# R7FA6T2BD register map
Vendor: Renesas Electronics Corporation; Series: RA6; File version: 1.40.00
CPU: CM33 r0p4, little endian, MPU, FPU, VTOR, 4 interrupt priority bits, 96 interrupts
Registers are 32-bit, read-write, reset 0x0 unless marked. A register's access mark holds for its fields unless they carry their own. Offsets are from the block's base; [hi:lo] are bit positions; {n}, {i} and the like mark numbered series.

## SYSC — System Control
Base 0x4001E000
0x0C SBYCR 16-bit reset 0x4000 — Standby Control Register
  [15] SSBY — Software Standby Mode Select
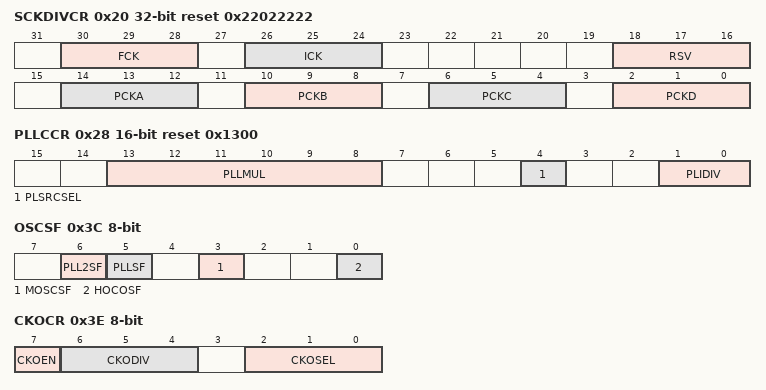
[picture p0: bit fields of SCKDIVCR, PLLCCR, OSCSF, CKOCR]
0x20 SCKDIVCR reset 0x22022222 — System Clock Division Control Register
  [30:28] FCK — FlashIF Clock (FCLK) Select
  [26:24] ICK — System Clock (ICLK) Select
  [18:16] RSV — Reserved. Set these bits to the same value as PCKB[2:0].
  [14:12] PCKA — Peripheral Module Clock A (PCLKA) Select
  [10:8] PCKB — Peripheral Module Clock B (PCLKB) Select
  [6:4] PCKC — Peripheral Module Clock C (PCLKC) Select
  [2:0] PCKD — Peripheral Module Clock D (PCLKD) Select
0x26 SCKSCR 8-bit reset 0x1 — System Clock Source Control Register
  [2:0] CKSEL — Clock Source Select
0x28 PLLCCR 16-bit reset 0x1300 — PLL Clock Control Register
  [13:8] PLLMUL range 0x13..0x3B — PLL Frequency Multiplication Factor Select
  [4] PLSRCSEL — PLL Clock Source Select
  [1:0] PLIDIV — PLL Input Frequency Division Ratio Select
0x2A PLLCR 8-bit reset 0x1 — PLL Control Register
  [0] PLLSTP — PLL Stop Control
0x32 MOSCCR 8-bit reset 0x1 — Main Clock Oscillator Control Register
  [0] MOSTP — Main Clock Oscillator Stop
0x36 HOCOCR 8-bit (reset mask 0xFE) — High,Speed On,Chip Oscillator Control Register
  [0] HCSTP — HOCO Stop
0x37 HOCOCR2 8-bit (reset mask 0xFC) — High,Speed On,Chip Oscillator Control Register 2
  [1:0] HCFRQ0 — HOCO Frequency Setting 0
0x38 MOCOCR 8-bit — Middle,Speed On,Chip Oscillator Control Register
  [0] MCSTP — MOCO Stop
0x3C OSCSF 8-bit ro (reset mask 0xFE) — Oscillation Stabilization Flag Register
  [6] PLL2SF — PLL2 Clock Oscillation Stabilization Flag
  [5] PLLSF — PLL Clock Oscillation Stabilization Flag
  [3] MOSCSF — Main Clock Oscillation Stabilization Flag
  [0] HOCOSF — HOCO Clock Oscillation Stabilization Flag
0x3E CKOCR 8-bit — Clock Out Control Register
  [7] CKOEN — Clock Out Enable
  [6:4] CKODIV — Clock Output Frequency Division Ratio
  [2:0] CKOSEL — Clock Out Source Select
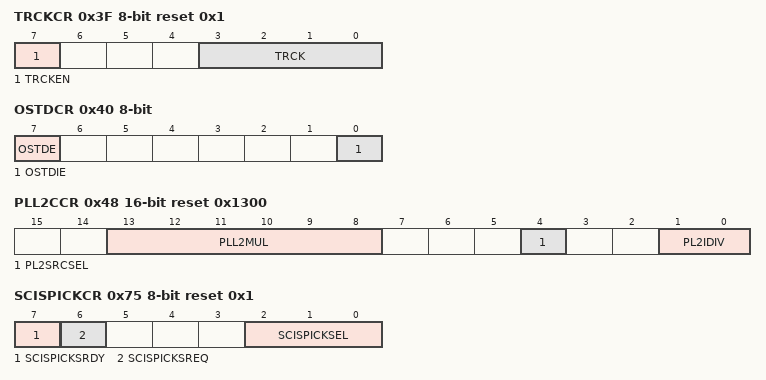
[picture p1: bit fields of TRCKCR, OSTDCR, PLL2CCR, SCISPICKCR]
0x3F TRCKCR 8-bit reset 0x1 — Trace Clock Control Register
  [7] TRCKEN — Trace Clock operating Enable
  [3:0] TRCK — Trace Clock operating frequency select
0x40 OSTDCR 8-bit — Oscillation Stop Detection Control Register
  [7] OSTDE — Oscillation Stop Detection Function Enable
  [0] OSTDIE — Oscillation Stop Detection Interrupt Enable
0x41 OSTDSR 8-bit — Oscillation Stop Detection Status Register
  [0] OSTDF — Oscillation Stop Detection Flag
0x48 PLL2CCR 16-bit reset 0x1300 — PLL2 Clock Control Register
  [13:8] PLL2MUL — PLL2 Frequency Multiplication Factor Select
  [4] PL2SRCSEL — PLL2 Clock Source Select
  [1:0] PL2IDIV — PLL2 Input Frequency Division Ratio Select
0x4A PLL2CR 8-bit reset 0x1 — PLL2 Control Register
  [0] PLL2STP — PLL2 Stop Control
0x61 MOCOUTCR 8-bit — MOCO User Trimming Control Register
  [7:0] MOCOUTRM — MOCO User Trimming
0x62 HOCOUTCR 8-bit — HOCO User Trimming Control Register
  [7:0] HOCOUTRM — HOCO User Trimming
0x6D SCISPICKDIVCR 8-bit — SCI SPI Clock Division Control Register
  [2:0] SCISPICKDIV — SCI SPI Clock (SCISPICLK) Division Select
0x6E CANFDCKDIVCR 8-bit — CANFD Clock Division Control Register
  [2:0] CANFDCKDIV — CANFD clock (CANFDCLK) Division Select
0x6F GPTCKDIVCR 8-bit — GPT Clock Division Control Register
  [2:0] GPTCKDIV — GPT clock (GPTCLK) Division Select
0x70 IICCKDIVCR 8-bit reset 0x1 — IIC Clock Division Control Register
  [2:0] IICCKDIV — IIC clock (IICCLK) Division Select
0x75 SCISPICKCR 8-bit reset 0x1 — SCI SPI Clock Control Register
  [7] SCISPICKSRDY ro — SCI SPI Clock (SCISPICLK) Switching Ready state flag
  [6] SCISPICKSREQ — SCI SPI Clock (SCISPICLK) Switching Request
  [2:0] SCISPICKSEL — SCI SPI Clock (SCISPICLK) Source Select
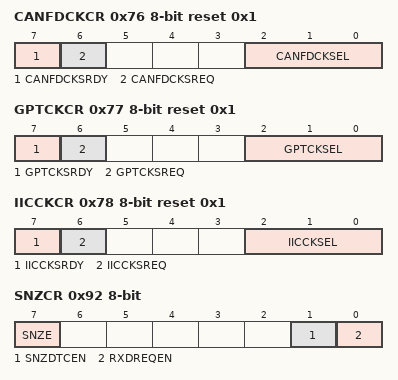
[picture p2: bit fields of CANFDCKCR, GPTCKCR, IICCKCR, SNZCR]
0x76 CANFDCKCR 8-bit reset 0x1 — CANFD Clock Control Register
  [7] CANFDCKSRDY ro — CANFD clock (CANFDCLK) Switching Ready state flag
  [6] CANFDCKSREQ — CANFD clock (CANFDCLK) Switching Request
  [2:0] CANFDCKSEL — CANFD clock (CANFDCLK) Source Select
0x77 GPTCKCR 8-bit reset 0x1 — GPT Clock Control Register
  [7] GPTCKSRDY ro — GPT clock (GPTCLK) Switching Ready state flag
  [6] GPTCKSREQ — GPT clock (GPTCLK) Switching Request
  [2:0] GPTCKSEL — GPT clock (GPTCLK) Source Select
0x78 IICCKCR 8-bit reset 0x1 — IIC Clock Control Register
  [7] IICCKSRDY ro — IIC clock (IICCLK) Switching Ready state flag
  [6] IICCKSREQ — IIC clock (IICCLK) Switching Request
  [2:0] IICCKSEL — IIC clock (IICCLK) Source Select
0x92 SNZCR 8-bit — Snooze Control Register
  [7] SNZE — Snooze mode Enable
  [1] SNZDTCEN — DTC Enable in Snooze mode
  [0] RXDREQEN — RXD0 Snooze Request Enable
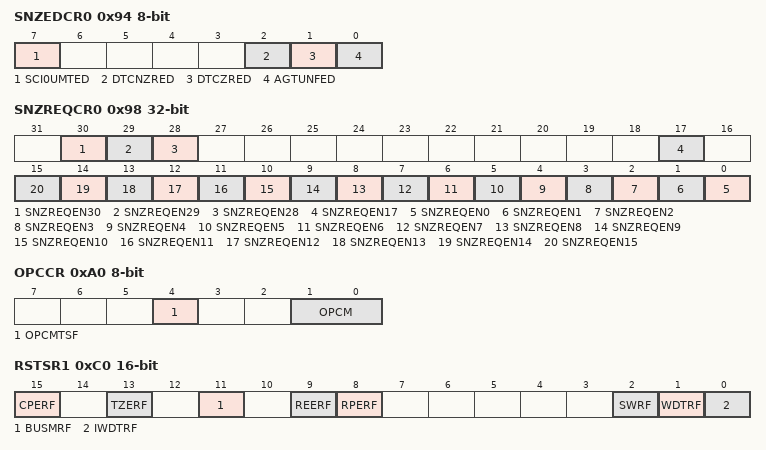
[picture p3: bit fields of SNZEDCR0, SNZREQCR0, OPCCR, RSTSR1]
0x94 SNZEDCR0 8-bit — Snooze End Control Register 0
  [7] SCI0UMTED — SCI0 Address Mismatch Snooze End Enable
  [2] DTCNZRED — Not Last DTC Transmission Completion Snooze End Enable
  [1] DTCZRED — Last DTC Transmission Completion Snooze End Enable
  [0] AGTUNFED — AGT1 Underflow Snooze End Enable
0x98 SNZREQCR0 — Snooze Request Control Register 0
  [30] SNZREQEN30 — Enable AGT1 compare match B snooze request
  [29] SNZREQEN29 — Enable AGT1 compare match A snooze request
  [28] SNZREQEN28 — Enable AGT1 underflow snooze request
  [17] SNZREQEN17 — Enable Key Interrupt snooze request
  [n] SNZREQEN{n} (n=0..15) — Enable IRQ{n} pin snooze request
0xA0 OPCCR 8-bit — Operating Power Control Register
  [4] OPCMTSF ro — Operating Power Control Mode Transition Status Flag
  [1:0] OPCM — Operating Power Control Mode Select
0xA2 MOSCWTCR 8-bit reset 0x5 — Main Clock Oscillator Wait Control Register
  [3:0] MSTS — Main Clock Oscillator Wait Time Setting
0xC0 RSTSR1 16-bit (reset mask 0x54F8) — Reset Status Register 1
  [15] CPERF — Cache Parity Error Reset Detect Flag
  [13] TZERF — TrustZone Error Reset Detect Flag
  [11] BUSMRF — Bus Master MPU Error Reset Detect Flag
  [9] REERF — SRAM ECC Error Reset Detect Flag
  [8] RPERF — SRAM Parity Error Reset Detect Flag
  [2] SWRF — Software Reset Detect Flag
  [1] WDTRF — Watchdog Timer Reset Detect Flag
  [0] IWDTRF — Independent Watchdog Timer Reset Detect Flag
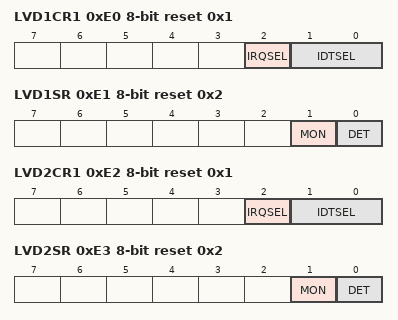
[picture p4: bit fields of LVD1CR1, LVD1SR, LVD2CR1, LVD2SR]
0xE0 LVD1CR1 8-bit reset 0x1 — Voltage Monitor 1 Circuit Control Register
  [2] IRQSEL — Voltage Monitor 1 Interrupt Type Select
  [1:0] IDTSEL — Voltage Monitor 1 Interrupt Generation Condition Select
0xE1 LVD1SR 8-bit reset 0x2 — Voltage Monitor 1 Circuit Status Register
  [1] MON ro — Voltage Monitor 1 Signal Monitor Flag
  [0] DET — Voltage Monitor 1 Voltage Variation Detection Flag
0xE2 LVD2CR1 8-bit reset 0x1 — Voltage Monitor 2 Circuit Control Register 1
  [2] IRQSEL — Voltage Monitor 2 Interrupt Type Select
  [1:0] IDTSEL — Voltage Monitor 2 Interrupt Generation Condition Select
0xE3 LVD2SR 8-bit reset 0x2 — Voltage Monitor 2 Circuit Status Register
  [1] MON ro — Voltage Monitor 2 Signal Monitor Flag
  [0] DET — Voltage Monitor 2 Voltage Variation Detection Flag
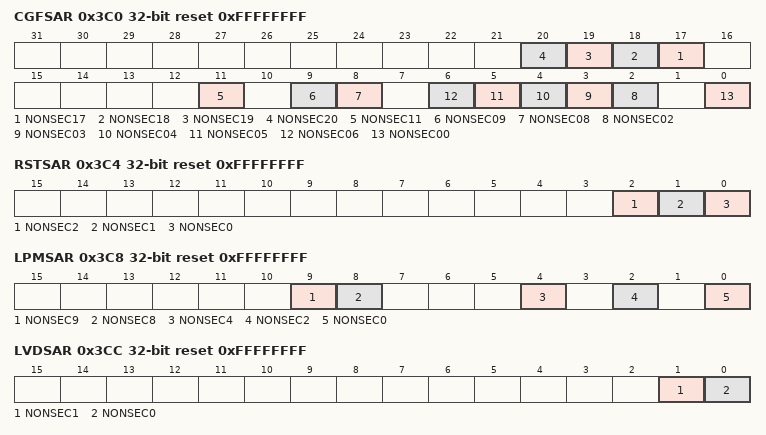
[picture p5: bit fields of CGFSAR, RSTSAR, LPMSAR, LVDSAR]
0x3C0 CGFSAR reset 0xFFFFFFFF — Clock Generation Function Security Attribute Register
  [n] NONSEC{n} (n=17..20) — Non Secure Attribute bit {n}
  [11] NONSEC11 — Non Secure Attribute bit 11
  [9] NONSEC09 — Non Secure Attribute bit 09
  [8] NONSEC08 — Non Secure Attribute bit 08
  [n] NONSEC{n:02} (n=2..6) — Non Secure Attribute bit {n:02}
  [0] NONSEC00 — Non Secure Attribute bit 00
0x3C4 RSTSAR reset 0xFFFFFFFF — Reset Security Attribution Register
  [2] NONSEC2 — Non Secure Attribute bit 2
  [1] NONSEC1 — Non Secure Attribute bit 1
  [0] NONSEC0 — Non Secure Attribute bit 0
0x3C8 LPMSAR reset 0xFFFFFFFF — Low Power Mode Security Attribution Register
  [9] NONSEC9 — Non Secure Attribute bit 9
  [8] NONSEC8 — Non Secure Attribute bit 8
  [4] NONSEC4 — Non Secure Attribute bit 4
  [2] NONSEC2 — Non Secure Attribute bit 2
  [0] NONSEC0 — Non Secure Attribute bit 0
0x3CC LVDSAR reset 0xFFFFFFFF — Low Voltage Detection Security Attribution Register
  [1] NONSEC1 — Non Secure Attribute bit 1
  [0] NONSEC0 — Non Secure Attribute bit 0
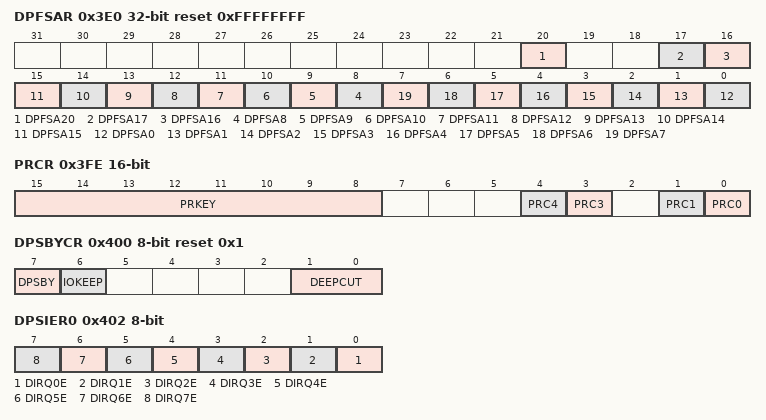
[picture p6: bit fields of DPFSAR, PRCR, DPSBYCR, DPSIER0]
0x3E0 DPFSAR reset 0xFFFFFFFF — Deep Software Standby Interrupt Factor Security Attribution Register
  [20] DPFSA20 — Deep Software Standby Interrupt Factor Security Attribute bit 20
  [17] DPFSA17 — Deep Software Standby Interrupt Factor Security Attribute bit 17
  [16] DPFSA16 — Deep Software Standby Interrupt Factor Security Attribute bit 16
  [n] DPFSA{n} (n=8..15) — Deep Software Standby Interrupt Factor Security Attribute bit n (n = 8 to 15)
  [n] DPFSA{n} (n=0..7) — Deep Software Standby Interrupt Factor Security Attribute bit n (n = 0 to 7)
0x3FE PRCR 16-bit — Protect Register
  [15:8] PRKEY wo — PRC Key Code
  [4] PRC4
  [3] PRC3 — Enable writing to the registers related to the LVD
  [1] PRC1 — Enable writing to the registers related to the low power modes
  [0] PRC0 — Enable writing to the registers related to the clock generation circuit
0x400 DPSBYCR 8-bit reset 0x1 — Deep Software Standby Control Register
  [7] DPSBY — Deep Software Standby
  [6] IOKEEP — I/O Port Rentention
  [1:0] DEEPCUT — Power,Supply Control
0x401 DPSWCR 8-bit reset 0x19 — Deep Software Standby Wait Control Register
  [5:0] WTSTS — Deep Software Wait Standby Time Setting Bit
0x402 DPSIER0 8-bit — Deep Software Standby Interrupt Enable Register 0
  [n] DIRQ{n}E (n=0..7) — IRQ{n}-DS Pin Enable
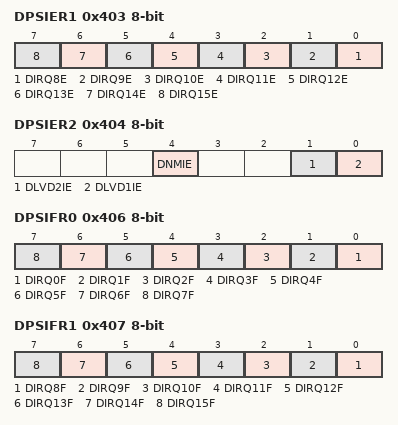
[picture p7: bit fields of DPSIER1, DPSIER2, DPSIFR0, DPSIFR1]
0x403 DPSIER1 8-bit — Deep Software Standby Interrupt Enable Register 1
  [n-8] DIRQ{n}E (n=8..15) — IRQ{n}-DS Pin Enable
0x404 DPSIER2 8-bit — Deep Software Standby Interrupt Enable Register 2
  [4] DNMIE — NMI Pin Enable
  [1] DLVD2IE — LVD2 Deep Software Standby Cancel Signal Enable
  [0] DLVD1IE — LVD1 Deep Software Standby Cancel Signal Enable
0x406 DPSIFR0 8-bit — Deep Software Standby Interrupt Flag Register 0
  [n] DIRQ{n}F (n=0..7) — IRQ{n}-DS Pin Deep Software Standby Cancel Flag
0x407 DPSIFR1 8-bit — Deep Software Standby Interrupt Flag Register 1
  [n-8] DIRQ{n}F (n=8..15) — IRQ{n}-DS Pin Deep Software Standby Cancel Flag
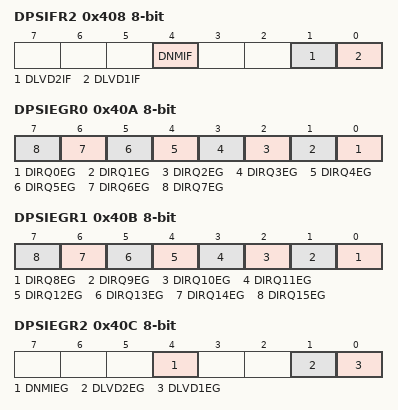
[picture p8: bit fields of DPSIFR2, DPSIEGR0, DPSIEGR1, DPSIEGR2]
0x408 DPSIFR2 8-bit — Deep Software Standby Interrupt Flag Register 2
  [4] DNMIF — NMI Pin Deep Software Standby Cancel Flag
  [1] DLVD2IF — LVD2 Deep Software Standby Cancel Flag
  [0] DLVD1IF — LVD1 Deep Software Standby Cancel Flag
0x40A DPSIEGR0 8-bit — Deep Software Standby Interrupt Edge Register 0
  [n] DIRQ{n}EG (n=0..7) — IRQ{n}-DS Pin Edge Select
0x40B DPSIEGR1 8-bit — Deep Software Standby Interrupt Edge Register 1
  [n-8] DIRQ{n}EG (n=8..15) — IRQ{n}-DS Pin Edge Select
0x40C DPSIEGR2 8-bit — Deep Software Standby Interrupt Edge Register 2
  [4] DNMIEG — NMI Pin Edge Select
  [1] DLVD2EG — LVD2 Edge Select
  [0] DLVD1EG — LVD1 Edge Select
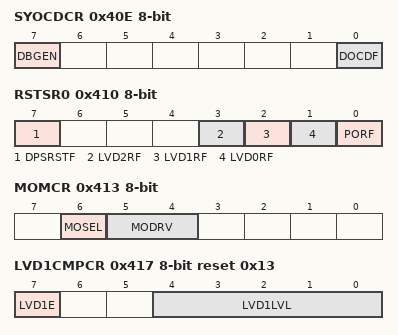
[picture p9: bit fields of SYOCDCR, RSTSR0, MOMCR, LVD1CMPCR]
0x40E SYOCDCR 8-bit (reset mask 0xFE) — System Control OCD Control Register
  [7] DBGEN — Debugger Enable bit
  [0] DOCDF — Deep Software Standby OCD flag
0x410 RSTSR0 8-bit (reset mask 0x70) — Reset Status Register 0
  [7] DPSRSTF — Deep Software Standby Reset Detect Flag
  [3] LVD2RF — Voltage Monitor 2 Reset Detect Flag
  [2] LVD1RF — Voltage Monitor 1 Reset Detect Flag
  [1] LVD0RF — Voltage Monitor 0 Reset Detect Flag
  [0] PORF — Power,On Reset Detect Flag
0x411 RSTSR2 8-bit (reset mask 0xFE) — Reset Status Register 2
  [0] CWSF — Cold/Warm Start Determination Flag
0x413 MOMCR 8-bit — Main Clock Oscillator Mode Oscillation Control Register
  [6] MOSEL — Main Clock Oscillator Switching
  [5:4] MODRV — Main Clock Oscillator Drive Capability 0 Switching
0x416 FWEPROR 8-bit reset 0x2 — Flash P/E Protect Register
  [1:0] FLWE — Flash Programming and Erasure
0x417 LVD1CMPCR 8-bit reset 0x13 — Voltage Monitoring 1 Comparator Control Register
  [7] LVD1E — Voltage Detection 1 Enable
  [4:0] LVD1LVL — Voltage Detection 1 Level Select (Standard voltage during drop in voltage)
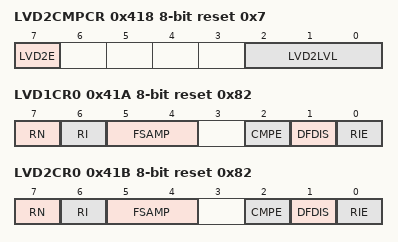
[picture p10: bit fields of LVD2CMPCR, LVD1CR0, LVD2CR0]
0x418 LVD2CMPCR 8-bit reset 0x7 — Voltage Monitoring 2 Comparator Control Register
  [7] LVD2E — Voltage Detection 2 Enable
  [2:0] LVD2LVL — Voltage Detection 2 Level Select (Standard voltage during drop in voltage)
0x41A LVD1CR0 8-bit reset 0x82 — Voltage Monitor 1 Circuit Control Register 0
  [7] RN — Voltage Monitor 1 Reset Negate Select
  [6] RI — Voltage Monitor 1 Circuit Mode Select
  [5:4] FSAMP — Sampling Clock Select
  [2] CMPE — Voltage Monitor 1 Circuit Comparison Result Output Enable
  [1] DFDIS — Voltage monitor 1 Digital Filter Disabled Mode Select
  [0] RIE — Voltage Monitor 1 Interrupt/Reset Enable
0x41B LVD2CR0 8-bit reset 0x82 — Voltage Monitor 2 Circuit Control Register 0
  [7] RN — Voltage Monitor 2 Reset Negate Select
  [6] RI — Voltage Monitor 2 Circuit Mode Select
  [5:4] FSAMP — Sampling Clock Select
  [2] CMPE — Voltage Monitor 2 Circuit Comparison Result Output Enable
  [1] DFDIS — Voltage monitor 2 Digital Filter Disabled Mode Select
  [0] RIE — Voltage Monitor 2 Interrupt/Reset Enable
0x490 LOCOCR 8-bit — Low,Speed On,Chip Oscillator Control Register
  [0] LCSTP — LOCO Stop
0x492 LOCOUTCR 8-bit — LOCO User Trimming Control Register
  [7:0] LOCOUTRM — LOCO User Trimming
